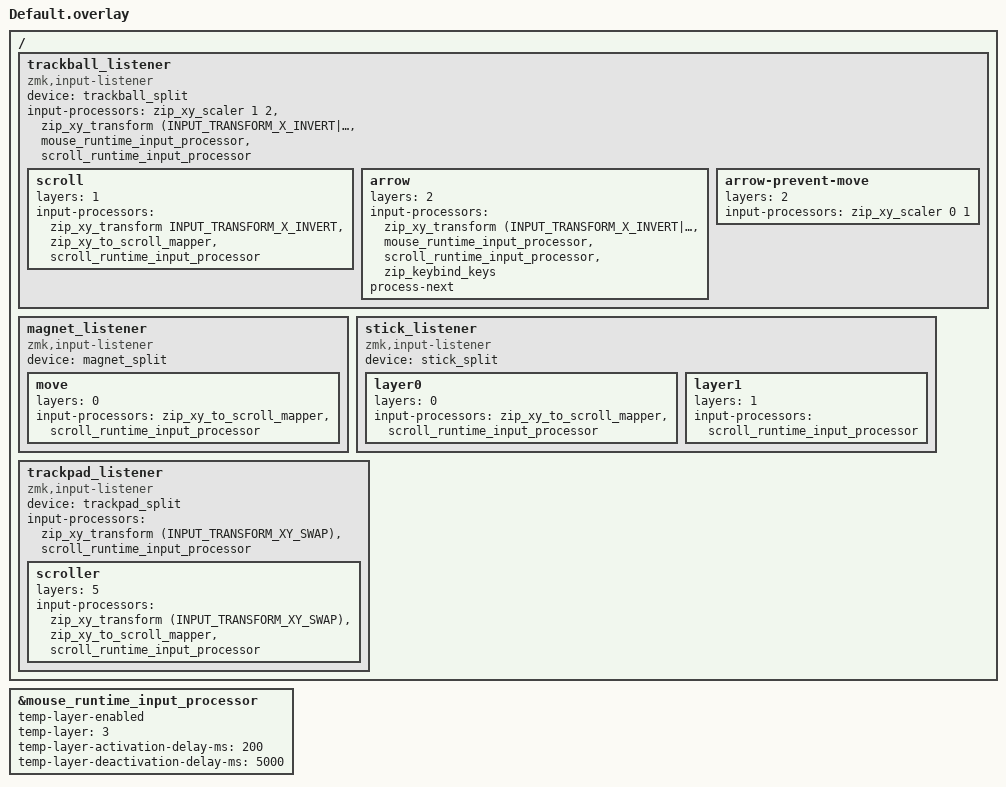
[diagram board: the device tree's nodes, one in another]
#include <input/processors/runtime-input-processor.dtsi>

/*
 * トラックボール使用中に自動でマウスレイヤー(3)へ切り替える設定。
 * activation-delay: 誤爆防止のため200ms継続して動かした場合のみ切り替わる。
 *   (遅延中にキー入力があればレイヤーは切り替わらない)
 * deactivation-delay: トラックボールを止めてから5秒後に元のレイヤーへ戻る。
 *   (マウスクリック以外のキーが押された場合は即座にデフォルトレイヤーへ戻る)
 */
&mouse_runtime_input_processor {
    temp-layer-enabled;
    temp-layer = <3>;
    temp-layer-activation-delay-ms = <200>;
    temp-layer-deactivation-delay-ms = <5000>;
};

/ {
    trackball_listener: trackball_listener {
        compatible = "zmk,input-listener";
        status = "okay";
        device = <&trackball_split>;
        input-processors = <&zip_xy_scaler 1 2>,
                           <&zip_xy_transform (INPUT_TRANSFORM_X_INVERT|INPUT_TRANSFORM_Y_INVERT)>,
                           <&mouse_runtime_input_processor &scroll_runtime_input_processor>;

        scroll {
            layers = <1>;
            input-processors = <&zip_xy_transform INPUT_TRANSFORM_X_INVERT>, 
                               <&zip_xy_to_scroll_mapper>, 
                               <&scroll_runtime_input_processor>;
        };

        arrow {
            layers = <2>;
            input-processors = <&zip_xy_transform (INPUT_TRANSFORM_X_INVERT|INPUT_TRANSFORM_Y_INVERT)>, 
                               <&mouse_runtime_input_processor &scroll_runtime_input_processor>,
                               <&zip_keybind_keys>;
            process-next;
        };
        
        arrow-prevent-move {
            layers = <2>;
            input-processors = <&zip_xy_scaler 0 1>;
        };
    };

    magnet_listener: magnet_listener {
        compatible = "zmk,input-listener";
        status = "okay";
        device = <&magnet_split>;
        move {
            layers = <0>;
            input-processors = <&zip_xy_to_scroll_mapper>, 
                               <&scroll_runtime_input_processor>;
        };
    };

    stick_listener: stick_listener {
        compatible = "zmk,input-listener";
        status = "okay";
        device = <&stick_split>;
        
        layer0 {
            layers = <0>;
            input-processors = <&zip_xy_to_scroll_mapper>, 
                               <&scroll_runtime_input_processor>;
        };
        layer1 {
            layers = <1>;
            input-processors = <&scroll_runtime_input_processor>;
        };
    };
    
    trackpad_listener: trackpad_listener {
        compatible = "zmk,input-listener";
        status = "okay";
        device = <&trackpad_split>;
        
        input-processors = <&zip_xy_transform (INPUT_TRANSFORM_XY_SWAP)>,
                           <&scroll_runtime_input_processor>;

        scroller {
            layers = <5>;
            input-processors = <&zip_xy_transform (INPUT_TRANSFORM_XY_SWAP)>,
                               <&zip_xy_to_scroll_mapper>, 
                               <&scroll_runtime_input_processor>;
        };
    };
};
